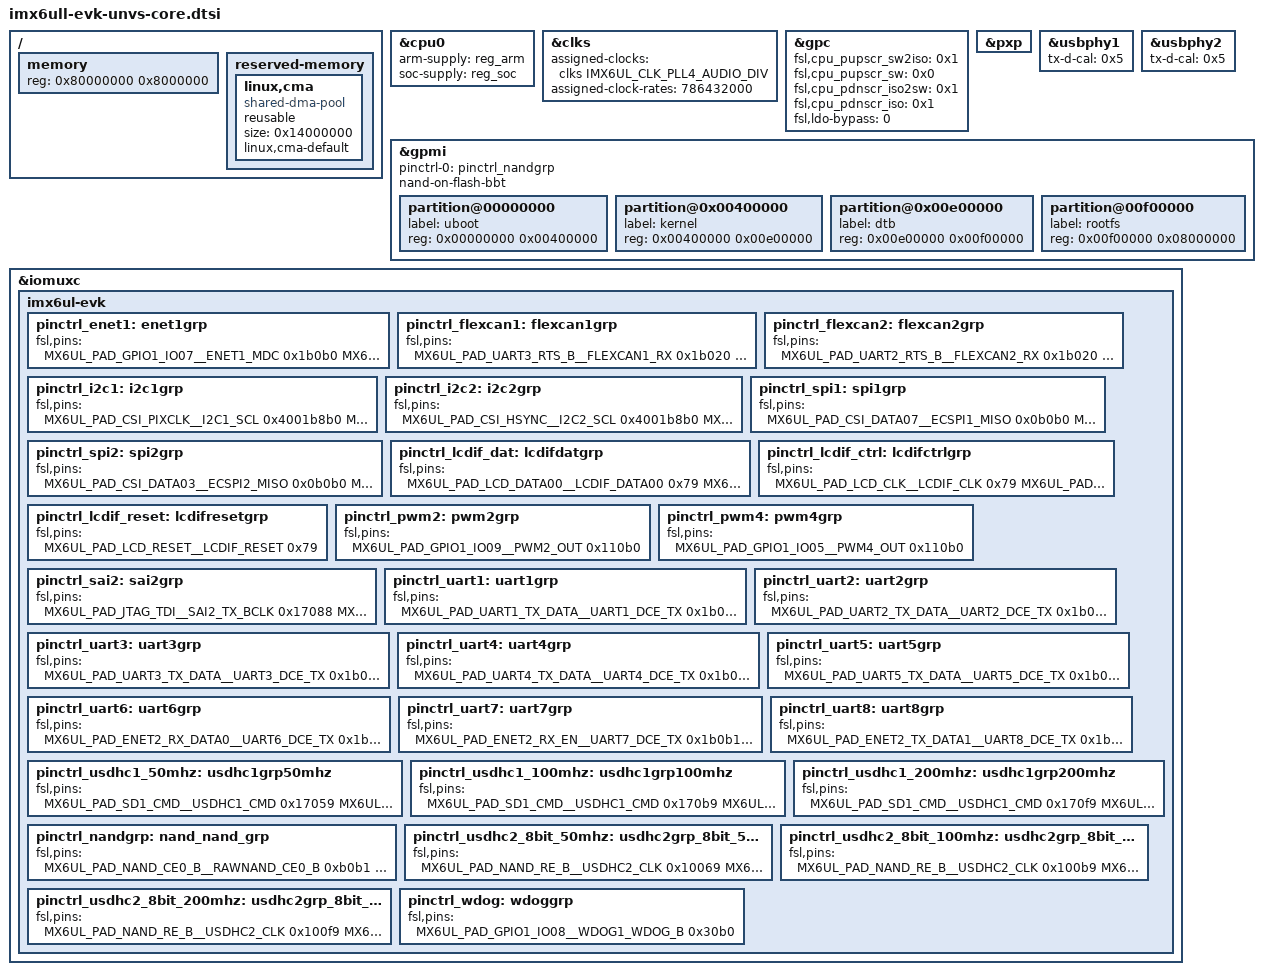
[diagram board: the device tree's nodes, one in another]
/*
 * Copyright (C) 2016 Freescale Semiconductor, Inc.
 * Copyright (C) 2019 Lierda, Inc.
 *
 * This program is free software; you can redistribute it and/or modify
 * it under the terms of the GNU General Public License version 2 as
 * published by the Free Software Foundation.
 */

#include <dt-bindings/input/input.h>
#include "imx6ull.dtsi"

/ {
	memory {
		reg = <0x80000000 0x8000000>;
	};

	reserved-memory {
		#address-cells = <1>;
		#size-cells = <1>;
		ranges;

		linux,cma {
			compatible = "shared-dma-pool";
			reusable;
			size = <0x14000000>;
			linux,cma-default;
		};
	};
};

&cpu0 {
	arm-supply = <&reg_arm>;
	soc-supply = <&reg_soc>;
};

&clks {
	assigned-clocks = <&clks IMX6UL_CLK_PLL4_AUDIO_DIV>;
	assigned-clock-rates = <786432000>;
};

&gpc {
	fsl,cpu_pupscr_sw2iso = <0x1>;
	fsl,cpu_pupscr_sw = <0x0>;
	fsl,cpu_pdnscr_iso2sw = <0x1>;
	fsl,cpu_pdnscr_iso = <0x1>;
	fsl,ldo-bypass = <0>; /* DCDC, ldo-enable */
};

&pxp {
	status = "okay";
};

&usbphy1 {
	tx-d-cal = <0x5>;
};

&usbphy2 {
	tx-d-cal = <0x5>;
};

/**
 * &usdhc2 {
 *	pinctrl-names = "default";
 *	pinctrl-0 = <&pinctrl_usdhc2_8bit_50mhz>;
 *	non-removable;
 *	status = "disabled";
 *};
 */

&gpmi {
	pinctrl-names = "default";
	pinctrl-0 = <&pinctrl_nandgrp>;
	status = "okay";
	nand-on-flash-bbt;

	partition@00000000 {
		label = "uboot";
		reg = <0x00000000 0x00400000>;
	};

	partition@0x00400000 {
		label = "kernel";
		reg = <0x00400000 0x00e00000>;
	};

	partition@0x00e00000 {
		label = "dtb";
		reg = <0x00e00000 0x00f00000>;
	};

	partition@00f00000 {
		label = "rootfs";
		reg = <0x00f00000 0x08000000>;
	};
};

&iomuxc {
	pinctrl-names = "default";

	imx6ul-evk {
		pinctrl_enet1: enet1grp {
			fsl,pins = <
				MX6UL_PAD_GPIO1_IO07__ENET1_MDC		0x1b0b0
				MX6UL_PAD_GPIO1_IO06__ENET1_MDIO	0x1b0b0
				MX6UL_PAD_ENET1_RX_EN__ENET1_RX_EN	0x1b0b0
				MX6UL_PAD_ENET1_RX_ER__ENET1_RX_ER	0x1b0b0
				MX6UL_PAD_ENET1_RX_DATA0__ENET1_RDATA00	0x1b0b0
				MX6UL_PAD_ENET1_RX_DATA1__ENET1_RDATA01	0x1b0b0
				MX6UL_PAD_ENET1_TX_EN__ENET1_TX_EN	0x1b0b0
				MX6UL_PAD_ENET1_TX_DATA0__ENET1_TDATA00	0x1b0b0
				MX6UL_PAD_ENET1_TX_DATA1__ENET1_TDATA01	0x1b0b0
				MX6UL_PAD_ENET1_TX_CLK__ENET1_REF_CLK1	0x4001b031

				MX6UL_PAD_UART1_CTS_B__GPIO1_IO18	0x80000000
			>;
		};

		pinctrl_flexcan1: flexcan1grp{
			fsl,pins = <
				MX6UL_PAD_UART3_RTS_B__FLEXCAN1_RX	0x1b020
				MX6UL_PAD_UART3_CTS_B__FLEXCAN1_TX	0x1b020
				MX6UL_PAD_ENET2_TX_CLK__GPIO2_IO14	0x80000000	
			>;
		};

		pinctrl_flexcan2: flexcan2grp{
			fsl,pins = <
				MX6UL_PAD_UART2_RTS_B__FLEXCAN2_RX	0x1b020
				MX6UL_PAD_UART2_CTS_B__FLEXCAN2_TX	0x1b020
			>;
		};

		pinctrl_i2c1: i2c1grp {
			fsl,pins = <
				MX6UL_PAD_CSI_PIXCLK__I2C1_SCL		0x4001b8b0
				MX6UL_PAD_CSI_MCLK__I2C1_SDA		0x4001b8b0
			>;
		};

		pinctrl_i2c2: i2c2grp {
			fsl,pins = <
				MX6UL_PAD_CSI_HSYNC__I2C2_SCL		0x4001b8b0
				MX6UL_PAD_CSI_VSYNC__I2C2_SDA		0x4001b8b0
			>;
		};

		pinctrl_spi1: spi1grp {
			fsl,pins = <
				MX6UL_PAD_CSI_DATA07__ECSPI1_MISO	0x0b0b0
				MX6UL_PAD_CSI_DATA06__ECSPI1_MOSI	0x0b0b0
				MX6UL_PAD_CSI_DATA05__ECSPI1_SS0	0x0b0b0
				MX6UL_PAD_CSI_DATA04__ECSPI1_SCLK	0x0b0b0
			>;
		};

		pinctrl_spi2: spi2grp {
			fsl,pins = <
				MX6UL_PAD_CSI_DATA03__ECSPI2_MISO	0x0b0b0
				MX6UL_PAD_CSI_DATA02__ECSPI2_MOSI	0x0b0b0
				MX6UL_PAD_CSI_DATA01__ECSPI2_SS0	0x0b0b0
				MX6UL_PAD_CSI_DATA00__ECSPI2_SCLK	0x0b0b0
			>;
		};

		pinctrl_lcdif_dat: lcdifdatgrp {
			fsl,pins = <
				MX6UL_PAD_LCD_DATA00__LCDIF_DATA00	0x79
				MX6UL_PAD_LCD_DATA01__LCDIF_DATA01	0x79
				MX6UL_PAD_LCD_DATA02__LCDIF_DATA02	0x79
				MX6UL_PAD_LCD_DATA03__LCDIF_DATA03	0x79
				MX6UL_PAD_LCD_DATA04__LCDIF_DATA04	0x79
				MX6UL_PAD_LCD_DATA05__LCDIF_DATA05	0x79
				MX6UL_PAD_LCD_DATA06__LCDIF_DATA06	0x79
				MX6UL_PAD_LCD_DATA07__LCDIF_DATA07	0x79
				MX6UL_PAD_LCD_DATA08__LCDIF_DATA08	0x79
				MX6UL_PAD_LCD_DATA09__LCDIF_DATA09	0x79
				MX6UL_PAD_LCD_DATA10__LCDIF_DATA10	0x79
				MX6UL_PAD_LCD_DATA11__LCDIF_DATA11	0x79
				MX6UL_PAD_LCD_DATA12__LCDIF_DATA12	0x79
				MX6UL_PAD_LCD_DATA13__LCDIF_DATA13	0x79
				MX6UL_PAD_LCD_DATA14__LCDIF_DATA14	0x79
				MX6UL_PAD_LCD_DATA15__LCDIF_DATA15	0x79
				MX6UL_PAD_LCD_DATA16__LCDIF_DATA16	0x79
				MX6UL_PAD_LCD_DATA17__LCDIF_DATA17	0x79
				MX6UL_PAD_LCD_DATA18__LCDIF_DATA18	0x79
				MX6UL_PAD_LCD_DATA19__LCDIF_DATA19	0x79
				MX6UL_PAD_LCD_DATA20__LCDIF_DATA20	0x79
				MX6UL_PAD_LCD_DATA21__LCDIF_DATA21	0x79
				MX6UL_PAD_LCD_DATA22__LCDIF_DATA22	0x79
				MX6UL_PAD_LCD_DATA23__LCDIF_DATA23	0x79
			>;
		};

		pinctrl_lcdif_ctrl: lcdifctrlgrp {
			fsl,pins = <
				MX6UL_PAD_LCD_CLK__LCDIF_CLK		0x79
				MX6UL_PAD_LCD_ENABLE__LCDIF_ENABLE	0x79
				MX6UL_PAD_LCD_HSYNC__LCDIF_HSYNC	0x79
				MX6UL_PAD_LCD_VSYNC__LCDIF_VSYNC	0x79
			>;
		};

		pinctrl_lcdif_reset: lcdifresetgrp {
			fsl,pins = <
				MX6UL_PAD_LCD_RESET__LCDIF_RESET	0x79
			>;
		};

		pinctrl_pwm2: pwm2grp {
			fsl,pins = <
				MX6UL_PAD_GPIO1_IO09__PWM2_OUT		0x110b0
			>;
		};

		pinctrl_pwm4: pwm4grp {
			fsl,pins = <
				MX6UL_PAD_GPIO1_IO05__PWM4_OUT		0x110b0
			>;
		};

		pinctrl_sai2: sai2grp {
			fsl,pins = <
				MX6UL_PAD_JTAG_TDI__SAI2_TX_BCLK	0x17088
				MX6UL_PAD_JTAG_TDO__SAI2_TX_SYNC	0x17088
				MX6UL_PAD_JTAG_TRST_B__SAI2_TX_DATA	0x11088
				MX6UL_PAD_JTAG_TCK__SAI2_RX_DATA	0x11088
				MX6UL_PAD_JTAG_TMS__SAI2_MCLK		0x17088
			>;
		};

		pinctrl_uart1: uart1grp {
			fsl,pins = <
				MX6UL_PAD_UART1_TX_DATA__UART1_DCE_TX	0x1b0b1
				MX6UL_PAD_UART1_RX_DATA__UART1_DCE_RX	0x1b0b1
			>;
		};

		pinctrl_uart2: uart2grp {
			fsl,pins = <
				MX6UL_PAD_UART2_TX_DATA__UART2_DCE_TX	0x1b0b1
				MX6UL_PAD_UART2_RX_DATA__UART2_DCE_RX 	0x1b0b1
			>;
		};

		pinctrl_uart3: uart3grp {
			fsl,pins = <
				MX6UL_PAD_UART3_TX_DATA__UART3_DCE_TX	0x1b0b1
				MX6UL_PAD_UART3_RX_DATA__UART3_DCE_RX 	0x1b0b1
			>;
		};

		pinctrl_uart4: uart4grp {
			fsl,pins = <
				MX6UL_PAD_UART4_TX_DATA__UART4_DCE_TX	0x1b0b1
				MX6UL_PAD_UART4_RX_DATA__UART4_DCE_RX 	0x1b0b1
			>;
		};

		pinctrl_uart5: uart5grp {
			fsl,pins = <
				MX6UL_PAD_UART5_TX_DATA__UART5_DCE_TX	0x1b0b1
				MX6UL_PAD_UART5_RX_DATA__UART5_DCE_RX 	0x1b0b1
			>;
		};

		pinctrl_uart6: uart6grp {
			fsl,pins = <
				MX6UL_PAD_ENET2_RX_DATA0__UART6_DCE_TX	0x1b0b1
				MX6UL_PAD_ENET2_RX_DATA1__UART6_DCE_RX 	0x1b0b1
			>;
		};

		pinctrl_uart7: uart7grp {
			fsl,pins = <
				MX6UL_PAD_ENET2_RX_EN__UART7_DCE_TX	0x1b0b1
				MX6UL_PAD_ENET2_TX_DATA0__UART7_DCE_RX 	0x1b0b1
			>;
		};

		pinctrl_uart8: uart8grp {
			fsl,pins = <
				MX6UL_PAD_ENET2_TX_DATA1__UART8_DCE_TX	0x1b0b1
				MX6UL_PAD_ENET2_TX_EN__UART8_DCE_RX 	0x1b0b1
			>;
		};

		pinctrl_usdhc1_50mhz: usdhc1grp50mhz {
			fsl,pins = <
				MX6UL_PAD_SD1_CMD__USDHC1_CMD		0x17059
				MX6UL_PAD_SD1_CLK__USDHC1_CLK		0x10071
				MX6UL_PAD_SD1_DATA0__USDHC1_DATA0	0x17059
				MX6UL_PAD_SD1_DATA1__USDHC1_DATA1	0x17059
				MX6UL_PAD_SD1_DATA2__USDHC1_DATA2	0x17059
				MX6UL_PAD_SD1_DATA3__USDHC1_DATA3	0x17059
			>;
		};

		pinctrl_usdhc1_100mhz: usdhc1grp100mhz {
			fsl,pins = <
				MX6UL_PAD_SD1_CMD__USDHC1_CMD		0x170b9
				MX6UL_PAD_SD1_CLK__USDHC1_CLK		0x100b9
				MX6UL_PAD_SD1_DATA0__USDHC1_DATA0	0x170b9
				MX6UL_PAD_SD1_DATA1__USDHC1_DATA1	0x170b9
				MX6UL_PAD_SD1_DATA2__USDHC1_DATA2	0x170b9
				MX6UL_PAD_SD1_DATA3__USDHC1_DATA3	0x170b9
			>;
		};

		pinctrl_usdhc1_200mhz: usdhc1grp200mhz {
			fsl,pins = <
				MX6UL_PAD_SD1_CMD__USDHC1_CMD		0x170f9
				MX6UL_PAD_SD1_CLK__USDHC1_CLK		0x100f9
				MX6UL_PAD_SD1_DATA0__USDHC1_DATA0	0x170f9
				MX6UL_PAD_SD1_DATA1__USDHC1_DATA1	0x170f9
				MX6UL_PAD_SD1_DATA2__USDHC1_DATA2	0x170f9
				MX6UL_PAD_SD1_DATA3__USDHC1_DATA3	0x170f9
			>;
		};

		pinctrl_nandgrp: nand_nand_grp {
			fsl,pins = <
				MX6UL_PAD_NAND_CE0_B__RAWNAND_CE0_B     0xb0b1
				MX6UL_PAD_NAND_ALE__RAWNAND_ALE         0xb0b1
				MX6UL_PAD_NAND_CLE__RAWNAND_CLE         0xb0b1
				MX6UL_PAD_NAND_RE_B__RAWNAND_RE_B       0xb0b1
				MX6UL_PAD_NAND_WE_B__RAWNAND_WE_B       0xb0b1
				MX6UL_PAD_NAND_WP_B__RAWNAND_WP_B       0xb0b1
				MX6UL_PAD_NAND_READY_B__RAWNAND_READY_B 0xb000
				MX6UL_PAD_NAND_DATA00__RAWNAND_DATA00   0xb0b1
				MX6UL_PAD_NAND_DATA01__RAWNAND_DATA01   0xb0b1
				MX6UL_PAD_NAND_DATA02__RAWNAND_DATA02   0xb0b1
				MX6UL_PAD_NAND_DATA03__RAWNAND_DATA03   0xb0b1
				MX6UL_PAD_NAND_DATA04__RAWNAND_DATA04   0xb0b1
				MX6UL_PAD_NAND_DATA05__RAWNAND_DATA05   0xb0b1
				MX6UL_PAD_NAND_DATA06__RAWNAND_DATA06   0xb0b1
				MX6UL_PAD_NAND_DATA07__RAWNAND_DATA07   0xb0b1
			>;
		};

		pinctrl_usdhc2_8bit_50mhz: usdhc2grp_8bit_50mhz {
			fsl,pins = <
				MX6UL_PAD_NAND_RE_B__USDHC2_CLK		0x10069
				MX6UL_PAD_NAND_WE_B__USDHC2_CMD		0x17059
				MX6UL_PAD_NAND_DATA00__USDHC2_DATA0	0x17059
				MX6UL_PAD_NAND_DATA01__USDHC2_DATA1	0x17059
				MX6UL_PAD_NAND_DATA02__USDHC2_DATA2	0x17059
				MX6UL_PAD_NAND_DATA03__USDHC2_DATA3	0x17059
				MX6UL_PAD_NAND_DATA04__USDHC2_DATA4	0x17059
				MX6UL_PAD_NAND_DATA05__USDHC2_DATA5	0x17059
				MX6UL_PAD_NAND_DATA06__USDHC2_DATA6	0x17059
				MX6UL_PAD_NAND_DATA07__USDHC2_DATA7	0x17059
			>;
		};

		pinctrl_usdhc2_8bit_100mhz: usdhc2grp_8bit_100mhz {
			fsl,pins = <
				MX6UL_PAD_NAND_RE_B__USDHC2_CLK		0x100b9
				MX6UL_PAD_NAND_WE_B__USDHC2_CMD		0x170b9
				MX6UL_PAD_NAND_DATA00__USDHC2_DATA0	0x170b9
				MX6UL_PAD_NAND_DATA01__USDHC2_DATA1	0x170b9
				MX6UL_PAD_NAND_DATA02__USDHC2_DATA2	0x170b9
				MX6UL_PAD_NAND_DATA03__USDHC2_DATA3	0x170b9
				MX6UL_PAD_NAND_DATA04__USDHC2_DATA4	0x170b9
				MX6UL_PAD_NAND_DATA05__USDHC2_DATA5	0x170b9
				MX6UL_PAD_NAND_DATA06__USDHC2_DATA6	0x170b9
				MX6UL_PAD_NAND_DATA07__USDHC2_DATA7	0x170b9
			>;
		};

		pinctrl_usdhc2_8bit_200mhz: usdhc2grp_8bit_200mhz {
			fsl,pins = <
				MX6UL_PAD_NAND_RE_B__USDHC2_CLK		0x100f9
				MX6UL_PAD_NAND_WE_B__USDHC2_CMD		0x170f9
				MX6UL_PAD_NAND_DATA00__USDHC2_DATA0	0x170f9
				MX6UL_PAD_NAND_DATA01__USDHC2_DATA1	0x170f9
				MX6UL_PAD_NAND_DATA02__USDHC2_DATA2	0x170f9
				MX6UL_PAD_NAND_DATA03__USDHC2_DATA3	0x170f9
				MX6UL_PAD_NAND_DATA04__USDHC2_DATA4	0x170f9
				MX6UL_PAD_NAND_DATA05__USDHC2_DATA5	0x170f9
				MX6UL_PAD_NAND_DATA06__USDHC2_DATA6	0x170f9
				MX6UL_PAD_NAND_DATA07__USDHC2_DATA7	0x170f9
			>;
		};

		pinctrl_wdog: wdoggrp {
			fsl,pins = <
				MX6UL_PAD_GPIO1_IO08__WDOG1_WDOG_B	0x30b0
			>;
		};
	};
};
